# DA14586 register map
Vendor: Dialog; Series: DA1458x; File version: 1.2
CPU: CM0 r1p0, little endian, MPU, FPU, 3 interrupt priority bits
Registers are 16-bit, read-write, reset 0x0 unless marked. A register's access mark holds for its fields unless they carry their own. Offsets are from the block's base; [hi:lo] are bit positions; {n}, {i} and the like mark numbered series; 'fields as' and 'values as' point back to an identical list.

## gpio580_ports_nl01 — gpio580_ports_nl01 registers
Base 0x50003000
0x00 P0_DATA_REG — P0 Data input / output register
  [7:0] P0_DATA — Set P0 output register when written; Returns the value of P0 port when read
0x02 P0_SET_DATA_REG — P0 Set port pins register
  [7:0] P0_SET — Writing a 1 to P0[y] sets P0[y] to 1. Writing 0 is discarded; Reading returns 0
0x04 P0_RESET_DATA_REG — P0 Reset port pins register
  [7:0] P0_RESET — Writing a 1 to P0[y] sets P0[y] to 0. Writing 0 is discarded; Reading returns 0
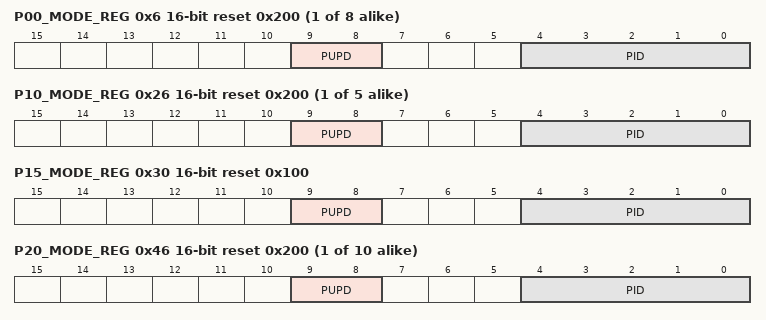
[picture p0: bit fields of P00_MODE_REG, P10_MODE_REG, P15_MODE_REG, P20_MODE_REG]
{0x6+2i} P{i:02}_MODE_REG reset 0x200 (i=0..7) — P{i:02} Mode Register
  [9:8] PUPD — 00 = Input, no resistors selected 01 = Input, pull-up selected 10 = Input, Pull-down selected 11 = Output, no resistors selected In ADC mode, these bits are don't care
  [4:0] PID — Function of port 0 = Port function, PUPD as set above 1 = UART1_RX 2 = UART1_TX 3 = UART2_RX 4 = UART2_TX 5 = SPI_DI 6 = SPI_DO 7 = SPI_CLK 8 = SPI_EN 9 = I2C_SCL 10 = I2C_SDA 11 = UART1_IRDA_RX 12 = UART1_IRDA_TX 13 = UART2_IRDA_RX 14 = UART2_IRDA_TX 15 = ADC (only for P0[3:0]) 16 = PWM0 17 = PWM1 18 = BLE_DIAG (only for P0[7:0]) 19 = UART1_CTSN 20 = UART1_RTSN 21 = UART2_CTSN 22 = UART2_RTSN 23 = PWM2 24 = PWM3 25 = PWM4 Note: when a certain input function (like SPI_DI) is selected on more than 1 port pin, the port with the lowest index has the highest priority and P0 has higher priority than P1.
0x20 P1_DATA_REG — P1 Data input / output register
  [7:0] P1_DATA — Set P1 output register when written; Returns the value of P1 port when read
0x22 P1_SET_DATA_REG — P1 Set port pins register
  [7:0] P1_SET — Writing a 1 to P1[y] sets P1[y] to 1. Writing 0 is discarded; Reading returns 0
0x24 P1_RESET_DATA_REG — P1 Reset port pins register
  [7:0] P1_RESET — Writing a 1 to P1[y] sets P1[y] to 0. Writing 0 is discarded; Reading returns 0
{0x12+2i} P{i}_MODE_REG reset 0x200 (i=10..14) — P{i} Mode Register
  [9:8] PUPD — 00 = Input, no resistors selected 01 = Input, pull-up selected 10 = Input, Pull-down selected 11 = Output, no resistors selected In analog mode, these bits are don't care P14_MODE_REG and P15_MODE_REG reset value is 1 (i.e. pulled up)
  [4:0] PID — See P0x_MODE_REG[PID]
0x30 P15_MODE_REG reset 0x100 — P15 Mode Register
  fields as P10_MODE_REG
0x40 P2_DATA_REG — P2 Data input / output register
  [9:0] P2_DATA — Set P2 output register when written; Returns the value of P2 port when read
0x42 P2_SET_DATA_REG — P2 Set port pins register
  [9:0] P2_SET — Writing a 1 to P2[y] sets P2[y] to 1. Writing 0 is discarded; Reading returns 0
0x44 P2_RESET_DATA_REG — P2 Reset port pins register
  [9:0] P2_RESET — Writing a 1 to P2[y] sets P2[y] to 0. Writing 0 is discarded; Reading returns 0
{0x1E+2i} P{i}_MODE_REG reset 0x200 (i=20..29) — P{i} Mode Register
  [9:8] PUPD — 00 = Input, no resistors selected 01 = Input, pull-up selected 10 = Input, Pull-down selected 11 = Output, no resistors selected In analog mode, these bits are don't care
  [4:0] PID — See P0x_MODE_REG[PID]
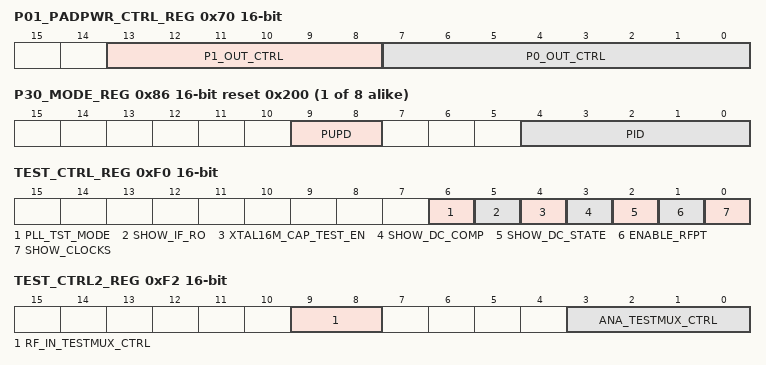
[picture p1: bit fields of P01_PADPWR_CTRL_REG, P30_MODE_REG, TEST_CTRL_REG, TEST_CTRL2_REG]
0x70 P01_PADPWR_CTRL_REG — Ports 0 and 1 Output Power Control Register
  [13:8] P1_OUT_CTRL — 1 = P1_x port output is powered by the 1 V rail 0 = P1_x port output is powered by the 3 V rail bit 8 controls the power of P1[0], bit 13 controls the power of P1[5]
  [7:0] P0_OUT_CTRL — 1 = P0_x port output is powered by the 1 V rail 0 = P0_x port output is powered by the 3 V rail bit 0 controls the power of P0[0], bit 7 controls the power of P0[7]
0x72 P2_PADPWR_CTRL_REG — Port 2 Output Power Control Register
  [9:0] P2_OUT_CTRL — 1 = P2_x port output is powered by the 1 V rail 0 = P2_x port output is powered by the 3 V rail bit 0 controls the power of P2[0], bit 9 controls the power of P2[9],
0x74 P3_PADPWR_CTRL_REG — Port 3 Output Power Control Register
  [7:0] P3_OUT_CTRL — 1 = P3_x port output is powered by the 1 V rail 0 = P3_x port output is powered by the 3 V rail bit 0 controls the power of P3[0], bit 7 controls the power of P3[7],
0x80 P3_DATA_REG — P3 Data input / output register
  [7:0] P3_DATA — Set P3 output register when written; Returns the value of P3 port when read
0x82 P3_SET_DATA_REG — P3 Set port pins register
  [7:0] P3_SET wo — Writing a 1 to P3[y] sets P3[y] to 1. Writing 0 is discarded; Reading returns 0
0x84 P3_RESET_DATA_REG — P3 Reset port pins register
  [7:0] P3_RESET wo — Writing a 1 to P0[y] sets P0[y] to 0. Writing 0 is discarded; Reading returns 0
{0x4A+2i} P{i}_MODE_REG reset 0x200 (i=30..37) — P{i} Mode Register
  [9:8] PUPD — 00 = Input, no resistors selected 01 = Input, pull-up selected 10 = Input, Pull-down selected 11 = Output, no resistors selected In ADC mode, these bits are don't care
  [4:0] PID — See P0x_MODE_REG[PID]
0xF0 TEST_CTRL_REG
  [6] PLL_TST_MODE — 0: Normal operation 1: Show the PLL test mode signals: P0[0] = RCLK P0[1] = NCLK P0[2] = CP_UP P0[3] = CP_DOWN Notes: - The control signal should go to the radio to enable this test mode.
  [5] SHOW_IF_RO — 0: Normal Port function. 1: Show IF filter Reference Oscillator I and Q signals. P0[0] = iff_ro_out_i P0[1] = iff_ro_out_q
  [4] XTAL16M_CAP_TEST_EN — 0: Normal Port function. 1: Show xtal16m_cap_test_outoutput P1[2:1] Notes: - The control signal should go to the radio to enable this test mode. - This register should be zero during scan test!
  [3] SHOW_DC_COMP — 0: normal port function 1: show signals to evaluate comparators in DCDC converter: P1[3:1] = dyn_sw_n[2:0]P1[0],P0[7:6] = dyn_sw[2:0]P0[5:3] = cont_sw[2:0] P0[2:0] = dcdc_test_out[2:0] (2=swout, 1=swp, 0=swn)
  [2] SHOW_DC_STATE — 0: normal port function 1: show signals to debug/evaluate the DCDC converter: P1[3] = ldo_dig_okP1[2] = ldo_otp_ok P1[1] = dcdc_idleP1[0] = dcdc_clk P0[7] = boost_vbat_ok P0[6] = vdcdc_okP0[5:0] = dcdc_test_out[5:0] (5=short, 4=bypass, 3=sw1v, 2=swout, 1=swp, 0=swn)
  [1] ENABLE_RFPT — 0: normal port function 1: enable the RF Production Test Unit. Used to store RX ADC samples or PLL TDC samples in SRAM. See RFPT_CTRL_REG, RFPT_ADDR_REG and RFPT_LEN_REG for details.
  [0] SHOW_CLOCKS — 0: normal port function 1: P0[5] = XTAL16M_clk P0[6] = XTAL32K_clk P0[7] = RC16M_clk P1[0] = RC32K_clk P1[1] = RC32K_Low_Jitter_clk
0xF2 TEST_CTRL2_REG
  [9:8] RF_IN_TESTMUX_CTRL — CConnect the RF input testbus to pins
  [3:0] ANA_TESTMUX_CTRL — Control of analog test bus switches: 0: all switches open 1: only switch 1 closed 2: only switch 2 closed 3: only switch 3 closed 4: only switch 4 closed 5: switches 1 & 2 closed 6: switches 1 & 4 closed 7: switches 2 & 3 closed 8: switches 3 & 4 closed
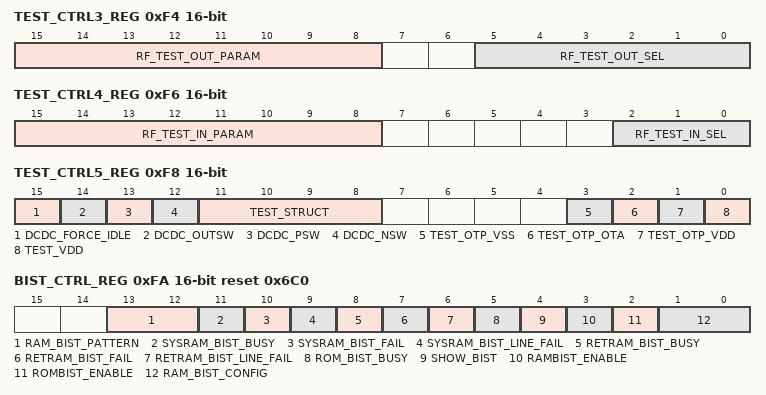
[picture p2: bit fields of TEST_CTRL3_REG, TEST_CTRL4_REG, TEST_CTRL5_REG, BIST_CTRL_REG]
0xF4 TEST_CTRL3_REG
  [15:8] RF_TEST_OUT_PARAM — Select which test will be enabled on the block selected by the RF output testbus (see
  [5:0] RF_TEST_OUT_SEL — Select a radio block to have its testbus connected to P1[1] and P1[2]. See Table 7 for more information. NOTE: all 0 represent no testmode and the testbusses are shorted to ground to prevent floating busses.
0xF6 TEST_CTRL4_REG
  [15:8] RF_TEST_IN_PARAM — Select which test will be enabled on the block selected by the RF output testbus (see
  [2:0] RF_TEST_IN_SEL — Select an RF block to have its test input connected to the input testbus at pins P0[0] and P0[3]. NOTE: all 0 represent no testmode and the testbusses are shorted to ground to prevent floating busses.
0xF8 TEST_CTRL5_REG
  [15] DCDC_FORCE_IDLE — Keep the DCDC-converter in the idle state.
  [14] DCDC_OUTSW — Close pMOS switch between 'switch' and 'vdcdc'
  [13] DCDC_PSW — Close pMOS switch between 'switch' and 'vbat3v'
  [12] DCDC_NSW — Close nMOS switch between 'switch' and 'gnd'
  [11:8] TEST_STRUCT — 4 bits to select which test-structure is mapped on P1[1] 0 : open 1 : VDD (1.2V) 2 : 10uA into 66k = 5/3 x 40k (W/L=0.45/22.33) 3 : 1uA into 700k = 18.5 x 40k (W/L=0.45/22.33) 4 : 1uA(same as going into 700k) 5 : AVS (0V) 6 : 5uA into nMOST (svt) 2x1u/110n 7 : 5uA into nMOST (hvt) 2x1u/110n 8 : 5uA into nMOST (UD18) 2x1u/260n 9 : 5uA into nMOST (OD33) 2x1u/500n a : 7.5uA into nMOST (na25) 4x1u/1.2u b : 5uA into nMOST (0vt) 4x1u/300n c : VDD - 5uA from pMOST (svt) 2x1u/110n d : VDD - 5uA from pMOST (hvt) 2x1u/110n e : VDD - 5uA from pMOST (OD33) 2x1u/400n f : VDD - 5uA from pMOST (UD18) 2x1u/260n
  [3] TEST_OTP_VSS — VSS_OTP (0V) mapped on P1[2]
  [2] TEST_OTP_OTA — Output of OTA inside LDO-OTP is mapped on P1[2]. This voltage will slowely rise due to capacitor leakage.
  [1] TEST_OTP_VDD — VDD_OTP on P1[2], 1uA bias sink on P1[1]
  [0] TEST_VDD — VDD on P1[1], VDD_REF (=ADC) on P1[2]
0xFA BIST_CTRL_REG reset 0x6C0
  [13:12] RAM_BIST_PATTERN — Pattern to use for the BIST tests: 00 = Use 0x5555 as test data 01 = Use 0x5A5A as test data 10 = Use 0x0000 as test data 11 = Use 0x0F0F as test data
  [11] SYSRAM_BIST_BUSY ro — Read version of bist status
  [10] SYSRAM_BIST_FAIL ro — Read version of bist status
  [9] SYSRAM_BIST_LINE_FAIL ro — Read version of bist status
  [8] RETRAM_BIST_BUSY ro — Read version of bist status
  [7] RETRAM_BIST_FAIL ro — Read version of bist status
  [6] RETRAM_BIST_LINE_FAIL ro — Read version of bist status
  [5] ROM_BIST_BUSY ro — Read version of bist status
  [4] SHOW_BIST — Map bist results on pins: P0[7] = SYSRAM_BIST_BUSY P0[6] = SYSRAM_BIST_FAIL P0[5] = SYSRAM_BIST_LINE_FAIL P0[4] = RETRAM_BIST_BUSY P0[3] = RETRAM_BIST_FAIL P0[2] = RETRAM_BIST_LINE_FAIL P0[1] = ROM_BIST_BUSY
  [3] RAMBIST_ENABLE — Enable the RAM bists
  [2] ROMBIST_ENABLE — Enable the ROM bist
  [1:0] RAM_BIST_CONFIG — Bist configuration: 00 = Perform all 8 phases 01 = Perform only phase 1 10 = Perform only phase 3 and 4 11 = Perform only phase 6
0xFC ROMBIST_RESULTL_REG
  [15:0] ROMBIST_RESULTL ro — Read version of bist status, result[15:0]
0xFE ROMBIST_RESULTH_REG
  [15:0] ROMBIST_RESULTH ro — Read version of bist status, result[31:16]
